# ATSAMA5D34 register map
Vendor: Microchip Technology; Series: SAMA5D3; File version: 0
Registers are 32-bit, read-write, reset 0x0 unless marked. A register's access mark holds for its fields unless they carry their own. Offsets are from the block's base; [hi:lo] are bit positions; {n}, {i} and the like mark numbered series.

## AES — Advanced Encryption Standard
Base 0xF8038000
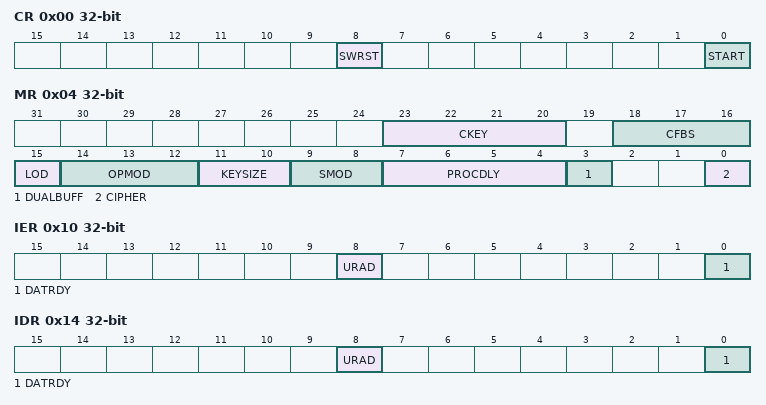
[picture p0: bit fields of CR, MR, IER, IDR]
0x00 CR wo — Control Register
  [8] SWRST — Software Reset
  [0] START — Start Processing
0x04 MR — Mode Register
  [23:20] CKEY — Key
    14=PASSWD (This field must be written with 0xE the first time the AES_MR is programmed. For subsequent programming of the AES_MR, any value can be written, including that of 0xE.Always reads as 0.)
  [18:16] CFBS — Cipher Feedback Data Size
    0=SIZE_128BIT (128-bit); 1=SIZE_64BIT (64-bit); 2=SIZE_32BIT (32-bit); 3=SIZE_16BIT (16-bit); 4=SIZE_8BIT (8-bit)
  [15] LOD — Last Output Data Mode
  [14:12] OPMOD — Operation Mode
    0=ECB (ECB: Electronic Code Book mode); 1=CBC (CBC: Cipher Block Chaining mode); 2=OFB (OFB: Output Feedback mode); 3=CFB (CFB: Cipher Feedback mode); 4=CTR (CTR: Counter mode (16-bit internal counter))
  [11:10] KEYSIZE
    0=AES128 (AES Key Size is 128 bits); 1=AES192 (AES Key Size is 192 bits); 2=AES256 (AES Key Size is 256 bits)
  [9:8] SMOD — Start Mode
    0=MANUAL_START (Manual Mode); 1=AUTO_START (Auto Mode); 2=IDATAR0_START (AES_IDATAR0 access only Auto Mode (DMA))
  [7:4] PROCDLY — Processing Delay
  [3] DUALBUFF — Dual Input Buffer
    0=INACTIVE (AES_IDATARx cannot be written during processing of previous block.); 1=ACTIVE (AES_IDATARx can be written during processing of previous block when SMOD = 2. It speeds up the overall runtime of large files.)
  [0] CIPHER — Processing Mode
0x10 IER wo — Interrupt Enable Register
  [8] URAD — Unspecified Register Access Detection Interrupt Enable
  [0] DATRDY — Data Ready Interrupt Enable
0x14 IDR wo — Interrupt Disable Register
  [8] URAD — Unspecified Register Access Detection Interrupt Disable
  [0] DATRDY — Data Ready Interrupt Disable
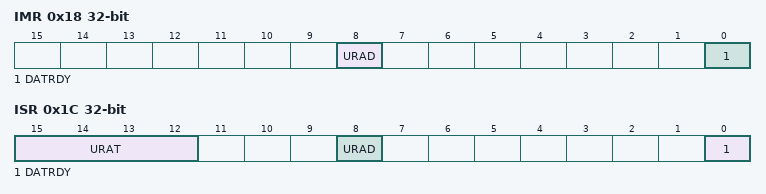
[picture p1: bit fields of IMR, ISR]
0x18 IMR ro — Interrupt Mask Register
  [8] URAD — Unspecified Register Access Detection Interrupt Mask
  [0] DATRDY — Data Ready Interrupt Mask
0x1C ISR ro — Interrupt Status Register
  [15:12] URAT — Unspecified Register Access (cleared by writing SWRST in AES_CR)
    0=IDR_WR_PROCESSING (Input Data Register written during the data processing when SMOD = 0x2 mode.); 1=ODR_RD_PROCESSING (Output Data Register read during the data processing.); 2=MR_WR_PROCESSING (Mode Register written during the data processing.); 3=ODR_RD_SUBKGEN (Output Data Register read during the sub-keys generation.); 4=MR_WR_SUBKGEN (Mode Register written during the sub-keys generation.); 5=WOR_RD_ACCESS (Write-only register read access.)
  [8] URAD — Unspecified Register Access Detection Status (cleared by writing SWRST in AES_CR)
  [0] DATRDY — Data Ready (cleared by setting bit START or bit SWRST in AES_CR or by reading AES_ODATARx)
{0x20+4i} KEYWR[{i}] (i=0..7) wo — Key Word Register
  [31:0] KEYW — Key Word
{0x40+4i} IDATAR[{i}] (i=0..3) wo — Input Data Register
  [31:0] IDATA — Input Data Word
{0x50+4i} ODATAR[{i}] (i=0..3) ro — Output Data Register
  [31:0] ODATA — Output Data
{0x60+4i} IVR[{i}] (i=0..3) wo — Initialization Vector Register
  [31:0] IV — Initialization Vector

## AIC — Advanced Interrupt Controller
Base 0xFFFFF000
0x00 SSR — Source Select Register
  [6:0] INTSEL — Interrupt Line Selection
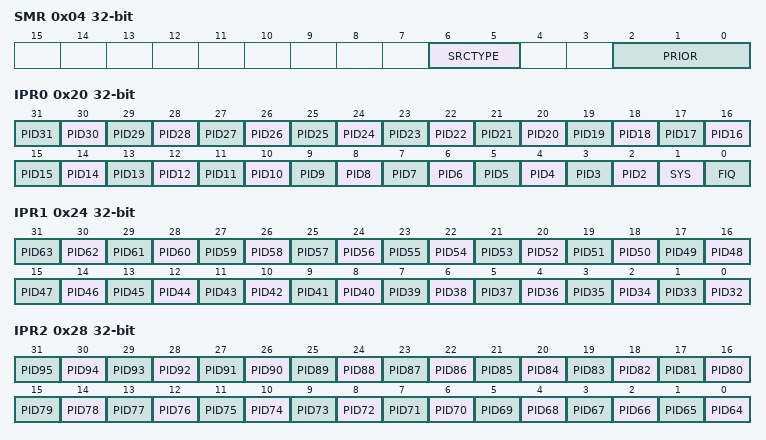
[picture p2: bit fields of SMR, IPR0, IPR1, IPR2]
0x04 SMR — Source Mode Register
  [6:5] SRCTYPE — Interrupt Source Type
    0=INT_LEVEL_SENSITIVE (High level Sensitive for internal sourceLow level Sensitive for external source); 1=INT_EDGE_TRIGGERED (Positive edge triggered for internal sourceNegative edge triggered for external source); 2=EXT_HIGH_LEVEL (High level Sensitive for internal sourceHigh level Sensitive for external source); 3=EXT_POSITIVE_EDGE (Positive edge triggered for internal sourcePositive edge triggered for external source)
  [2:0] PRIOR — Priority Level
0x08 SVR — Source Vector Register
  [31:0] VECTOR — Source Vector
0x10 IVR ro — Interrupt Vector Register
  [31:0] IRQV
0x14 FVR ro — FIQ Vector Register
  [31:0] FIQV
0x18 ISR ro — Interrupt Status Register
  [6:0] IRQID — Current Interrupt Identifier
0x20 IPR0 ro — Interrupt Pending Register 0
  [n] PID{n} (n=2..31) — Interrupt Pending
  [1] SYS — Interrupt Pending
  [0] FIQ — Interrupt Pending
0x24 IPR1 ro — Interrupt Pending Register 1
  [n-32] PID{n} (n=32..63) — Interrupt Pending
0x28 IPR2 ro — Interrupt Pending Register 2
  [n-64] PID{n} (n=64..95) — Interrupt Pending
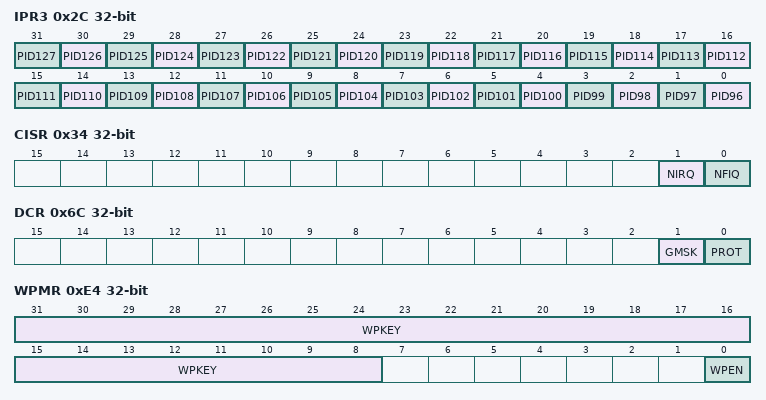
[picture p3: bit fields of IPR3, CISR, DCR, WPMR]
0x2C IPR3 ro — Interrupt Pending Register 3
  [n-96] PID{n} (n=96..127) — Interrupt Pending
0x30 IMR ro — Interrupt Mask Register
  [0] INTM — Interrupt Mask
0x34 CISR ro — Core Interrupt Status Register
  [1] NIRQ — NIRQ Status
  [0] NFIQ — NFIQ Status
0x38 EOICR wo — End of Interrupt Command Register
  [0] ENDIT — Interrupt Processing Complete Command
0x3C SPU — Spurious Interrupt Vector Register
  [31:0] SIVR
0x40 IECR wo — Interrupt Enable Command Register
  [0] INTEN — Interrupt Enable
0x44 IDCR wo — Interrupt Disable Command Register
  [0] INTD — Interrupt Disable
0x48 ICCR wo — Interrupt Clear Command Register
  [0] INTCLR — Interrupt Clear
0x4C ISCR wo — Interrupt Set Command Register
  [0] INTSET — Interrupt Set
0x50 FFER wo — Fast Forcing Enable Register
  [0] FFEN — Fast Forcing Enable
0x54 FFDR wo — Fast Forcing Disable Register
  [0] FFDIS — Fast Forcing Disable
0x58 FFSR ro — Fast Forcing Status Register
  [0] FFS — Fast Forcing Status
0x6C DCR — Debug Control Register
  [1] GMSK — General Interrupt Mask
  [0] PROT — Protection Mode
0xE4 WPMR — Write Protection Mode Register
  [31:8] WPKEY — Write Protection Key
    0x414943=PASSWD (Writing any other value in this field aborts the write operation of the WPEN bit.Always reads as 0.)
  [0] WPEN — Write Protection Enable
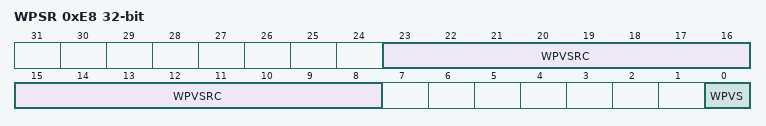
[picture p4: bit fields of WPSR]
0xE8 WPSR ro — Write Protection Status Register
  [23:8] WPVSRC — Write Protection Violation Source
  [0] WPVS — Write Protection Violation Status
